AUTOSAR XML (schema 4-2-2)
package /AUTOLIV/SoftwareComponents/SpiIf
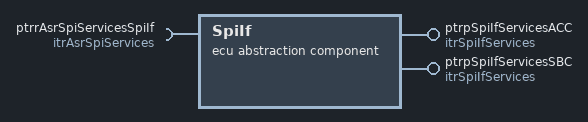
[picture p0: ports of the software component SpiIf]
  ecu abstraction sw component type SpiIf: category=MCAL_Communication_Drivers
    provide port ptrpSpiIfServicesACC: provided-interface=itrSpiIfServices  # # Architecture Element ID - ARCH_SW_SpiIf_ptrpSpiIfServicesACC_writeSpiData # Description - The runnable shall write the {Spi Data} content on the Spi internal buffer of the selected {Spi Channel Id} - The runnable shall send the {Spi Sequence} on the Spi bus # Data Flow ## Inputs - {Spi Channel Sequence} - {Spi Data} ## Outputs # Linked Runnable - SpiIf_writeSpiData #Traceability ------------------------------------------------------------------------------------ # Architecture Element ID - ARCH_SW_SpiIf_ptrpSpiIfServicesACC_spiSyncTransmitSequence # Description - The runnable shall transmit the selected {Spi Sequence} on the Spi bus # Data Flow ## Inputs - {Spi Sequence} ## Outputs # Linked Runnable - SpiIf_spiSyncTransmitSequence #Traceability ------------------------------------------------------------------------------------ Architecture Element ID - ARCH_SW_SpiIf_ptrpSpiIfServicesACC_spiReadIBFromChannel # Description - The runnable shall read the Spi data response from the accelerometer on the {Spi Response Data} output parameter # Data Flow ## Inputs - {Spi Channel Id} ## Outputs - {Spi Response Data} # Linked Runnable - SpiIf_spiReadIBFromChannel #Traceability
    provide port ptrpSpiIfServicesSBC: provided-interface=itrSpiIfServices  # # Architecture Element ID - ARCH_SW_SpiIf_ptrpSpiIfServicesSBC_writeSpiData # Description - The runnable shall write the {Spi Data} content on the Spi internal buffer of the selected {Spi Channel Id} - The runnable shall send the {Spi Sequence} on the Spi bus # Data Flow ## Inputs - {Spi Channel Sequence} - {Spi Data} ## Outputs # Linked Runnable - SpiIf_writeSpiData #Traceability ------------------------------------------------------------------------------------ # Architecture Element ID - ARCH_SW_SpiIf_ptrpSpiIfServicesSBC_spiSyncTransmitSequence # Description - The runnable shall transmit the selected {Spi Sequence} on the Spi bus # Data Flow ## Inputs - {Spi Sequence} ## Outputs # Linked Runnable - SpiIf_spiSyncTransmitSequence #Traceability ------------------------------------------------------------------------------------ Architecture Element ID - ARCH_SW_SpiIf_ptrpSpiIfServicesSBC_spiReadIBFromChannel # Description - The runnable shall read the Spi data response from the SBC chip on the {Spi Response Data} output parameter # Data Flow ## Inputs - {Spi Channel Id} ## Outputs - {Spi Response Data} # Linked Runnable - SpiIf_spiReadIBFromChannel #Traceability
    require port ptrrAsrSpiServicesSpiIf: required-interface=itrAsrSpiServices  # Architecture Element ID - ARCH_SW_SpiIf_ptrrAsrSpiServices_Spi_WriteIB_SpiIf_writeSpiData # Description - The runnable shall pass the {Spi Channel Id} and {Spi Data} input parameters to the Spi_WriteIB interface in order to send data on the Spi bus # Data Flow ## Inputs - {Spi Channel Sequence} - {Spi Data} ## Outputs # Linked Runnable - SpiIf_writeSpiData #Traceability ------------------------------------------------------------------------------------ Architecture Element ID - ARCH_SW_SpiIf_ptrrAsrSpiServices_Spi_SyncTransmit_SpiIf_writeSpiData # Description - The Spi_SyncTransmit interface shall be called in order to transmit the selected {Spi Sequence} on the Spi bus # Data Flow ## Inputs - {Spi Channel Sequence} - {Spi Data} ## Outputs # Linked Runnable - SpiIf_writeSpiData #Traceability ------------------------------------------------------------------------------------ # Architecture Element ID - ARCH_SW_SpiIf_ptrrAsrSpiServices_Spi_SyncTransmit_SpiIf_spiSyncTransmitSequence # Description - The Spi_SyncTransmit interface shall be called in order to transmit the selected {Spi Sequence} on the Spi bus # Data Flow ## Inputs - {Spi Sequence} ## Outputs # Linked Runnable - SpiIf_spiSyncTransmitSequence #Traceability ------------------------------------------------------------------------------------ Architecture Element ID - ARCH_SW_SpiIf_ptrrAsrSpiServices_spiReadIBFromChannel # Description - The Spi_ReadIB interface will be called in order to read the Spi data response from the slave and forward in to the rest of the Application BSW modules(e.g. SBC/ACC) on the {Spi Response Data} output parameter # Data Flow ## Inputs - {Spi Channel Id} ## Outputs - {Spi Response Data} # Linked Runnable - SpiIf_spiReadIBFromChannel #Traceability
